# STM32G0B1VET6 register map
File version: 1.0
Registers are 32-bit, access not given, reset 0x0 unless marked. A register's access mark holds for its fields unless they carry their own. Offsets are from the block's base; [hi:lo] are bit positions; {n}, {i} and the like mark numbered series; 'fields as' and 'values as' point back to an identical list.

## TAMP
Base 0x4000B000
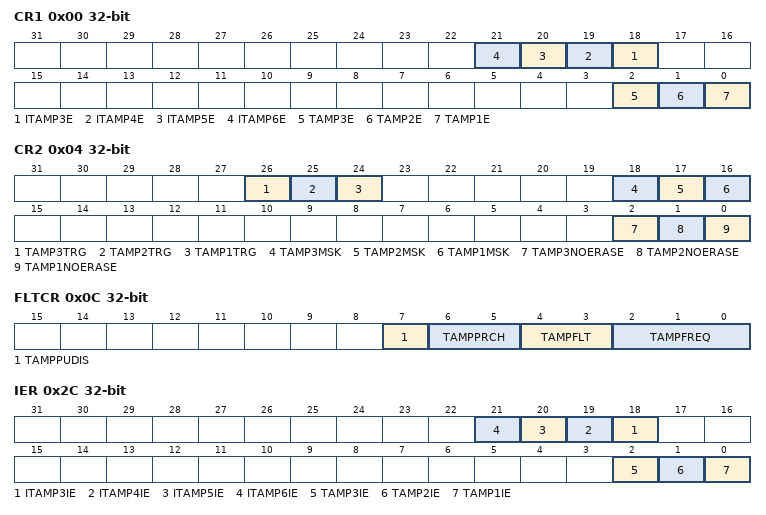
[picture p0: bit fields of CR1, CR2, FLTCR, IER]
0x00 CR1
  [n+15] ITAMP{n}E (n=3..6), [2] TAMP3E, [1] TAMP2E, [0] TAMP1E
0x04 CR2
  [26] TAMP3TRG, [25] TAMP2TRG, [24] TAMP1TRG, [18] TAMP3MSK, [17] TAMP2MSK, [16] TAMP1MSK, [2] TAMP3NOERASE, [1] TAMP2NOERASE, [0] TAMP1NOERASE
0x0C FLTCR
  [7] TAMPPUDIS, [6:5] TAMPPRCH, [4:3] TAMPFLT, [2:0] TAMPFREQ
0x2C IER
  [n+15] ITAMP{n}IE (n=3..6), [2] TAMP3IE, [1] TAMP2IE, [0] TAMP1IE
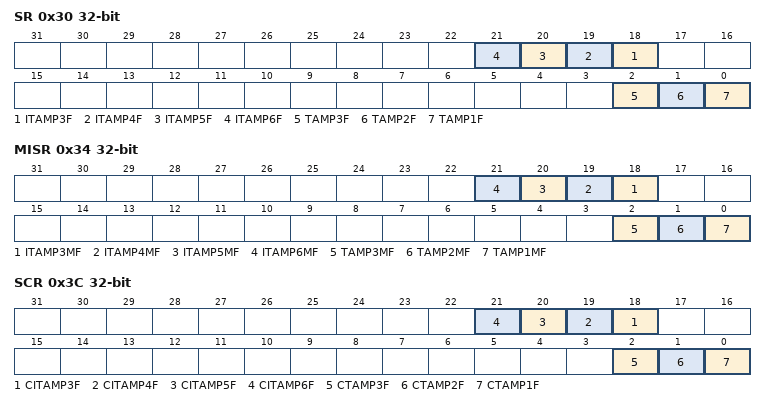
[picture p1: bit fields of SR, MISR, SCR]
0x30 SR
  [n+15] ITAMP{n}F (n=3..6), [2] TAMP3F, [1] TAMP2F, [0] TAMP1F
0x34 MISR
  [n+15] ITAMP{n}MF (n=3..6), [2] TAMP3MF, [1] TAMP2MF, [0] TAMP1MF
0x3C SCR
  [n+15] CITAMP{n}F (n=3..6), [2] CTAMP3F, [1] CTAMP2F, [0] CTAMP1F
{0x100+4i} BKP{i}R (i=0..4)

## SYSCFG
Base 0x40010000
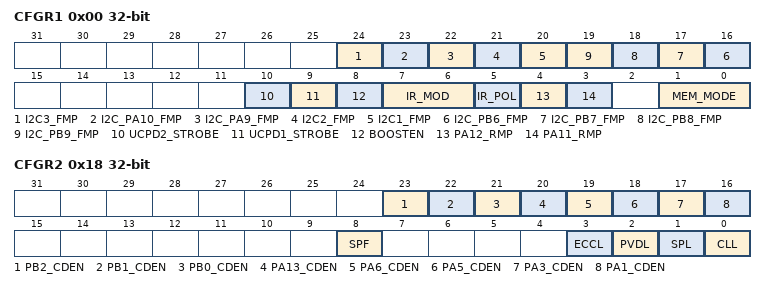
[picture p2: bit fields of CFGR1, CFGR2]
0x00 CFGR1
  [24] I2C3_FMP, [23] I2C_PA10_FMP, [22] I2C_PA9_FMP, [21] I2C2_FMP, [20] I2C1_FMP, [n+10] I2C_PB{n}_FMP (n=6..9), [10] UCPD2_STROBE, [9] UCPD1_STROBE, [8] BOOSTEN, [7:6] IR_MOD, [5] IR_POL, [4] PA12_RMP, [3] PA11_RMP, [1:0] MEM_MODE
0x18 CFGR2
  [23] PB2_CDEN, [22] PB1_CDEN, [21] PB0_CDEN, [20] PA13_CDEN, [19] PA6_CDEN, [18] PA5_CDEN, [17] PA3_CDEN, [16] PA1_CDEN, [8] SPF, [3] ECCL, [2] PVDL, [1] SPL, [0] CLL
0x80 IT_LINE_SR.0
0x84 IT_LINE_SR.1
0x88 IT_LINE_SR.2
0x8C IT_LINE_SR.3
0x90 IT_LINE_SR.4
0x94 IT_LINE_SR.5
0x98 IT_LINE_SR.6
0x9C IT_LINE_SR.7
0xA0 IT_LINE_SR.8
0xA4 IT_LINE_SR.9
0xA8 IT_LINE_SR.10
0xAC IT_LINE_SR.11
0xB0 IT_LINE_SR.12
0xB4 IT_LINE_SR.13
0xB8 IT_LINE_SR.14
0xBC IT_LINE_SR.15
0xC0 IT_LINE_SR.16
0xC4 IT_LINE_SR.17
0xC8 IT_LINE_SR.18
0xCC IT_LINE_SR.19
0xD0 IT_LINE_SR.20
0xD4 IT_LINE_SR.21
0xD8 IT_LINE_SR.22
0xDC IT_LINE_SR.23
0xE0 IT_LINE_SR.24
0xE4 IT_LINE_SR.25
0xE8 IT_LINE_SR.26
0xEC IT_LINE_SR.27
0xF0 IT_LINE_SR.28
0xF4 IT_LINE_SR.29
0xF8 IT_LINE_SR.30
0xFC IT_LINE_SR.31

## VREFBUF
Base 0x40010030
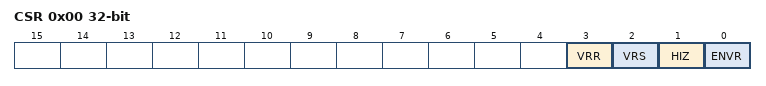
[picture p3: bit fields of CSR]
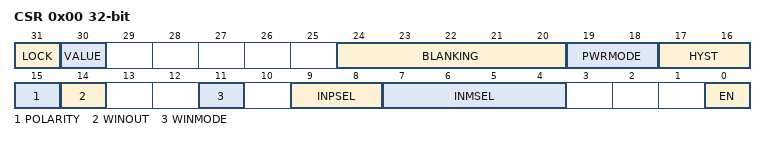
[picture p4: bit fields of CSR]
0x00 CSR
  [3] VRR, [2] VRS, [1] HIZ, [0] ENVR
0x04 CCR
  [5:0] TRIM

## COMP1
Base 0x40010200
Same registers: COMP2 0x40010204, COMP3 0x40010208
0x00 CSR
  [31] LOCK, [30] VALUE, [24:20] BLANKING, [19:18] PWRMODE, [17:16] HYST, [15] POLARITY, [14] WINOUT, [11] WINMODE, [9:8] INPSEL, [7:4] INMSEL, [0] EN

## COMP12_COMMON
Base 0x40010200
Same registers: COMP23_COMMON 0x40010204
0x00 CSR_ODD
0x04 CSR_EVEN

## ADC1
Base 0x40012400
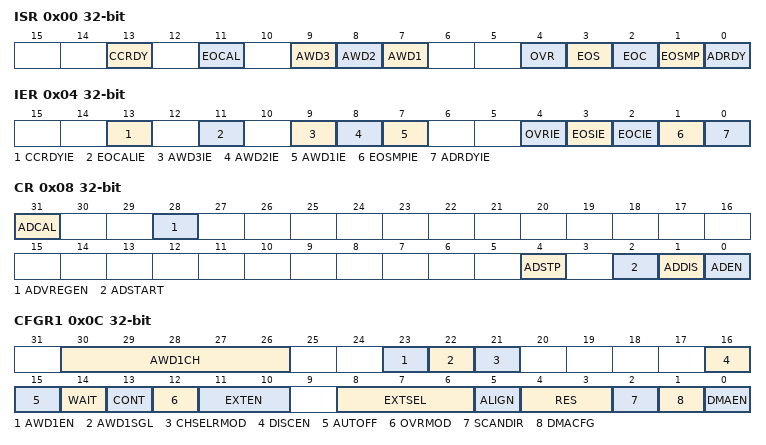
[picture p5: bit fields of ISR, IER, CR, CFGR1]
0x00 ISR
  [13] CCRDY, [11] EOCAL, [9] AWD3, [8] AWD2, [7] AWD1, [4] OVR, [3] EOS, [2] EOC, [1] EOSMP, [0] ADRDY
0x04 IER
  [13] CCRDYIE, [11] EOCALIE, [9] AWD3IE, [8] AWD2IE, [7] AWD1IE, [4] OVRIE, [3] EOSIE, [2] EOCIE, [1] EOSMPIE, [0] ADRDYIE
0x08 CR
  [31] ADCAL, [28] ADVREGEN, [4] ADSTP, [2] ADSTART, [1] ADDIS, [0] ADEN
0x0C CFGR1
  [30:26] AWD1CH, [23] AWD1EN, [22] AWD1SGL, [21] CHSELRMOD, [16] DISCEN, [15] AUTOFF, [14] WAIT, [13] CONT, [12] OVRMOD, [11:10] EXTEN, [8:6] EXTSEL, [5] ALIGN, [4:3] RES, [2] SCANDIR, [1] DMACFG, [0] DMAEN
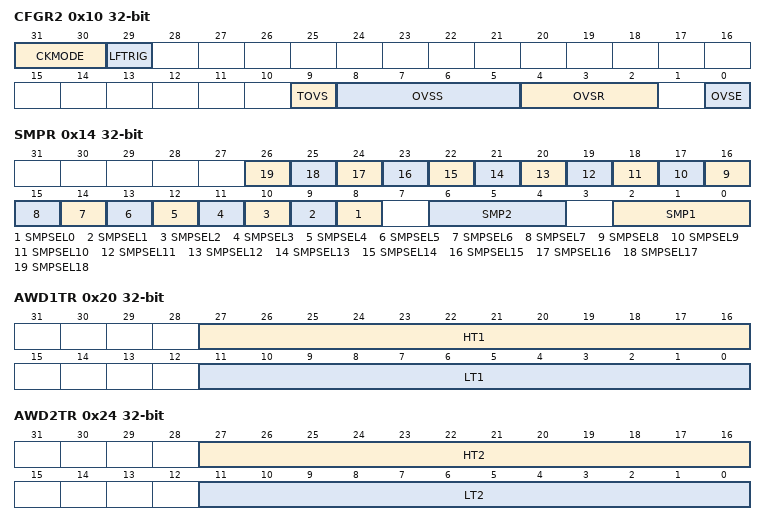
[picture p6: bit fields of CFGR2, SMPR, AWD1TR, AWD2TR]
0x10 CFGR2
  [31:30] CKMODE, [29] LFTRIG, [9] TOVS, [8:5] OVSS, [4:2] OVSR, [0] OVSE
0x14 SMPR
  [n+8] SMPSEL{n} (n=0..18), [6:4] SMP2, [2:0] SMP1
0x20 AWD1TR
  [27:16] HT1, [11:0] LT1
0x24 AWD2TR
  [27:16] HT2, [11:0] LT2
0x28 CHSELR
  [4n-1:4n-4] SQ{n} (n=2..8), [18] CHSEL18, [17] CHSEL17, [15] CHSEL15, [14] CHSEL14, [13] CHSEL13, [11] CHSEL11, [10] CHSEL10, [9] CHSEL9, [7] CHSEL7, [6] CHSEL6, [5] CHSEL5, [3] CHSEL3, [2] CHSEL2, [1] CHSEL1, [31:0] SQ_ALL
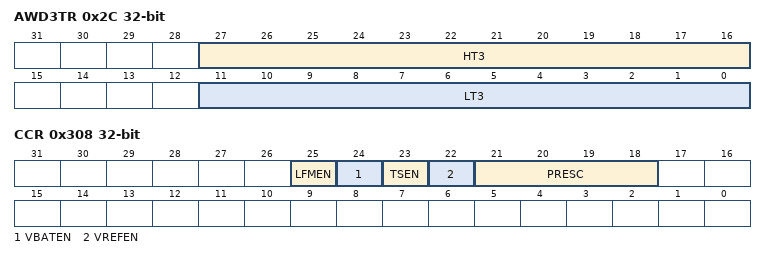
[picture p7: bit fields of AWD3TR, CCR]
0x2C AWD3TR
  [27:16] HT3, [11:0] LT3
0x40 DR
  [15:0] DATA
0xA0 AWD2CR
  [18:0] AWD2CH
0xA4 AWD3CR
  [18:0] AWD3CH
0xB4 CALFACT
  [6:0] CALFACT
0x308 CCR
  [25] LFMEN, [24] VBATEN, [23] TSEN, [22] VREFEN, [21:18] PRESC

## DBG
Base 0x40015800
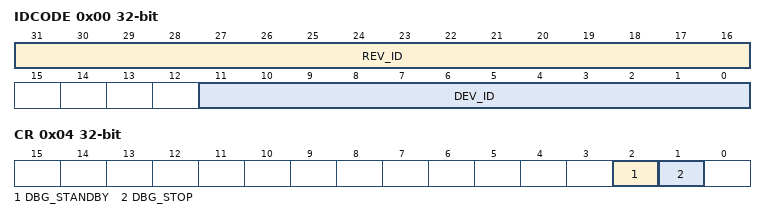
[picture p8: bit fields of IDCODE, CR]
0x00 IDCODE
  [31:16] REV_ID, [11:0] DEV_ID
0x04 CR
  [2] DBG_STANDBY, [1] DBG_STOP
0x08 APBFZ1
0x0C APBFZ2

## DMA1
Base 0x40020000
Same registers: DMA2 0x40020400
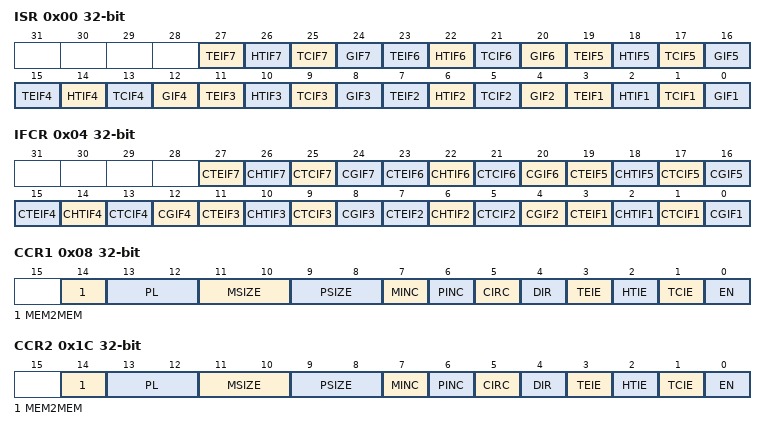
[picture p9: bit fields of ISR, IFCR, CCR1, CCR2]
0x00 ISR
  [4n-1] TEIF{n} (n=1..7), [4n-2] HTIF{n} (n=1..7), [4n-3] TCIF{n} (n=1..7), [4n-4] GIF{n} (n=1..7)
0x04 IFCR
  [4n-1] CTEIF{n} (n=1..7), [4n-2] CHTIF{n} (n=1..7), [4n-3] CTCIF{n} (n=1..7), [4n-4] CGIF{n} (n=1..7)
0x08 CCR1
  [14] MEM2MEM, [13:12] PL, [11:10] MSIZE, [9:8] PSIZE, [7] MINC, [6] PINC, [5] CIRC, [4] DIR, [3] TEIE, [2] HTIE, [1] TCIE, [0] EN
0x0C CNDTR1
  [15:0] NDT
0x10 CPAR1
  [31:0] PA
{0x0+0x14*i} CMAR{i} (i=1..7)
  [31:0] MA
0x1C CCR2
  fields as CCR1
0x20 CNDTR2
  [15:0] NDT
0x24 CPAR2
  [31:0] PA
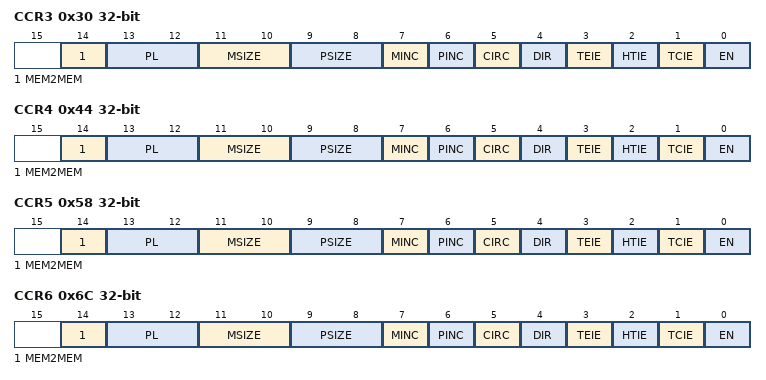
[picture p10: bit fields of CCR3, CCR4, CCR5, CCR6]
0x30 CCR3
  fields as CCR1
0x34 CNDTR3
  [15:0] NDT
0x38 CPAR3
  [31:0] PA
0x44 CCR4
  fields as CCR1
0x48 CNDTR4
  [15:0] NDT
0x4C CPAR4
  [31:0] PA
0x58 CCR5
  fields as CCR1
0x5C CNDTR5
  [15:0] NDT
0x60 CPAR5
  [31:0] PA
0x6C CCR6
  fields as CCR1
0x70 CNDTR6
  [15:0] NDT
0x74 CPAR6
  [31:0] PA
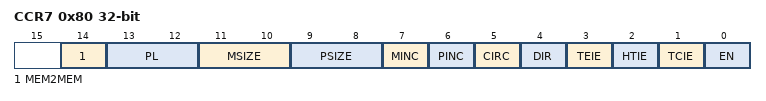
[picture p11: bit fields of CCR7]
0x80 CCR7
  fields as CCR1
0x84 CNDTR7
  [15:0] NDT
0x88 CPAR7
  [31:0] PA
